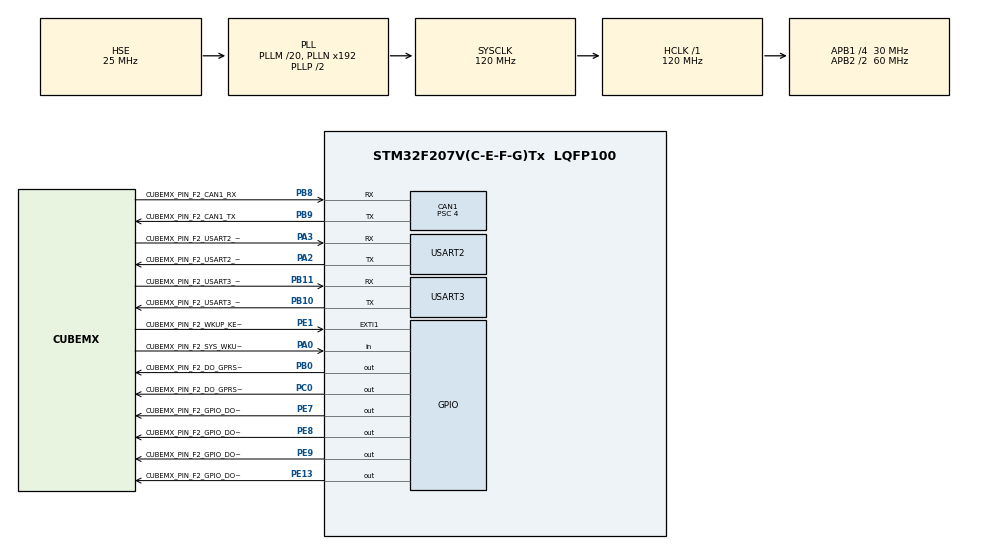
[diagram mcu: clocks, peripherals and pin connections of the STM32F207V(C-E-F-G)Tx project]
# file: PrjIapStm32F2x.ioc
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CAN1.ABOM=ENABLE
CAN1.BS1=CAN_BS1_12TQ
CAN1.BS2=CAN_BS2_2TQ
CAN1.CalculateTimeBit=2000
CAN1.CalculateTimeQuantum=133.33333333333334
CAN1.Prescaler=4
FREERTOS.INCLUDE_eTaskGetState=1
FREERTOS.INCLUDE_pcTaskGetTaskName=1
FREERTOS.INCLUDE_vTaskCleanUpResources=1
FREERTOS.Queues01=myQueue01,16,uint16_t,NULL
FREERTOS.Tasks01=defaultTask,0,512,StartDefaultTask,Default;myTask02,0,512,StartTask02,Default
FREERTOS.Timers01=myTimer01,Callback01,osTimerPeriodic,Default
FREERTOS.configCHECK_FOR_STACK_OVERFLOW=2
FREERTOS.configGENERATE_RUN_TIME_STATS=1
FREERTOS.configMAX_PRIORITIES=31
FREERTOS.configMAX_TASK_NAME_LEN=24
FREERTOS.configMINIMAL_STACK_SIZE=256
FREERTOS.configQUEUE_REGISTRY_SIZE=4
FREERTOS.configTOTAL_HEAP_SIZE=0xCC00
FREERTOS.configUSE_COUNTING_SEMAPHORES=1
FREERTOS.configUSE_IDLE_HOOK=1
FREERTOS.configUSE_MALLOC_FAILED_HOOK=1
FREERTOS.configUSE_PORT_OPTIMISED_TASK_SELECTION=1
FREERTOS.configUSE_RECURSIVE_MUTEXES=1
FREERTOS.configUSE_TICKLESS_IDLE=1
FREERTOS.configUSE_TICK_HOOK=1
FREERTOS.configUSE_TIMERS=1
Mcu.Family=STM32F2
Mcu.Name=STM32F207V(C-E-F-G)Tx
Mcu.Package=LQFP100
NVIC.CAN1_RX0_IRQn=true\:0\:0\:false\:false\:true\:false
NVIC.CAN1_RX1_IRQn=true\:0\:0\:false\:false\:true\:false
NVIC.PriorityGroup=NVIC_PRIORITYGROUP_4
NVIC.TIM1_UP_TIM10_IRQn=true\:0\:0\:false\:false\:true\:false
NVIC.TimeBase=TIM1_UP_TIM10_IRQn
NVIC.TimeBaseIP=TIM1
NVIC.USART2_IRQn=true\:5\:0\:false\:true\:true\:1\:true
NVIC.USART3_IRQn=true\:5\:0\:false\:true\:true\:2\:true
PA0-WKUP.GPIO_Label=CUBEMX_PIN_F2_SYS_WKUP_KEY1
PA0-WKUP.GPIO_PuPd=GPIO_PULLDOWN
PA0-WKUP.Signal=GPIO_Input
PA13.GPIO_Label=CUBEMX_PIN_F2_SYS_JTMS_SWIDO
PA13.Mode=JTAG_5_pins
PA13.Signal=SYS_JTMS-SWDIO
PA14.GPIO_Label=CUBEMX_PIN_F2_SYS_JTCK_SWCLK
PA14.Mode=JTAG_5_pins
PA14.Signal=SYS_JTCK-SWCLK
PA15.GPIO_Label=CUBEMX_PIN_F2_SYS_JDTI
PA15.Mode=JTAG_5_pins
PA15.Signal=SYS_JTDI
PA2.GPIO_Label=CUBEMX_PIN_F2_USART2_TX_GPRS
PA2.Mode=Asynchronous
PA2.Signal=USART2_TX
PA3.GPIO_Label=CUBEMX_PIN_F2_USART2_RX_GPRS
PA3.Mode=Asynchronous
PA3.Signal=USART2_RX
PB0.GPIO_Label=CUBEMX_PIN_F2_DO_GPRSMOD_PWR_SUPPLY
PB0.GPIO_ModeDefaultOutputPP=GPIO_MODE_OUTPUT_PP
PB0.GPIO_PuPd=GPIO_NOPULL
PB0.GPIO_Speed=GPIO_SPEED_FREQ_MEDIUM
PB0.PinState=GPIO_PIN_RESET
PB0.Signal=GPIO_Output
PB10.GPIO_Label=CUBEMX_PIN_F2_USART3_TX_PRINT
PB10.Mode=Asynchronous
PB10.Signal=USART3_TX
PB11.GPIO_Label=CUBEMX_PIN_F2_USART3_RX_PRINT
PB11.Mode=Asynchronous
PB11.Signal=USART3_RX
PB3.GPIO_Label=CUBEMX_PIN_F2_SYS_JTDO_SWO
PB3.Mode=JTAG_5_pins
PB3.Signal=SYS_JTDO-SWO
PB4.GPIO_Label=CUBEMX_PIN_F2_SYS_JTRST
PB4.Mode=JTAG_5_pins
PB4.Signal=SYS_JTRST
PB8.GPIO_Label=CUBEMX_PIN_F2_CAN1_RX
PB8.Mode=Master
PB8.Signal=CAN1_RX
PB9.GPIO_Label=CUBEMX_PIN_F2_CAN1_TX
PB9.Mode=Master
PB9.Signal=CAN1_TX
PC0.GPIO_Label=CUBEMX_PIN_F2_DO_GPRSMOD_PWR_KEY
PC0.GPIO_ModeDefaultOutputPP=GPIO_MODE_OUTPUT_OD
PC0.PinState=GPIO_PIN_SET
PC0.Signal=GPIO_Output
PC14-OSC32_IN.GPIO_Label=CUBEMX_PIN_F2_RCC_OS32_IN
PC14-OSC32_IN.Mode=LSE-External-Oscillator
PC14-OSC32_IN.Signal=RCC_OSC32_IN
PC15-OSC32_OUT.GPIO_Label=CUBEMX_PIN_F2_RCC_OSC32_OUT
PC15-OSC32_OUT.Mode=LSE-External-Oscillator
PC15-OSC32_OUT.Signal=RCC_OSC32_OUT
PE1.GPIO_Label=CUBEMX_PIN_F2_WKUP_KEY2
PE1.Signal=GPXTI1
PE13.GPIO_Label=CUBEMX_PIN_F2_GPIO_DO_BEEP
PE13.Signal=GPIO_Output
PE7.GPIO_Label=CUBEMX_PIN_F2_GPIO_DO_LED_POWER
PE7.Signal=GPIO_Output
PE8.GPIO_Label=CUBEMX_PIN_F2_GPIO_DO_LED_COMMU
PE8.Signal=GPIO_Output
PE9.GPIO_Label=CUBEMX_PIN_F2_GPIO_DO_LED_WORK_STATE
PE9.Signal=GPIO_Output
PH0-OSC_IN.GPIO_Label=CUBEMX_PIN_F2_RCC_OSC_IN
PH0-OSC_IN.Mode=HSE-External-Oscillator
PH0-OSC_IN.Signal=RCC_OSC_IN
PH1-OSC_OUT.GPIO_Label=CUBEMX_PIN_F2_RCC_OSC_OUT
PH1-OSC_OUT.Mode=HSE-External-Oscillator
PH1-OSC_OUT.Signal=RCC_OSC_OUT
ProjectManager.HeapSize=0x200
ProjectManager.StackSize=0x400
ProjectManager.TargetToolchain=MDK-ARM V5
RCC.48MHZClocksFreq_Value=48000000
RCC.AHBFreq_Value=120000000
RCC.APB1CLKDivider=RCC_HCLK_DIV4
RCC.APB1Freq_Value=30000000
RCC.APB1TimFreq_Value=60000000
RCC.APB2CLKDivider=RCC_HCLK_DIV2
RCC.APB2Freq_Value=60000000
RCC.APB2TimFreq_Value=120000000
RCC.CortexFreq_Value=120000000
RCC.FLatency=FLASH_LATENCY_3
RCC.HCLKFreq_Value=120000000
RCC.HSE_VALUE=25000000
RCC.HSI_VALUE=16000000
RCC.PLLM=20
RCC.PLLQ=5
RCC.PLLSourceVirtual=RCC_PLLSOURCE_HSE
RCC.SYSCLKFreq_VALUE=120000000
RCC.SYSCLKSource=RCC_SYSCLKSOURCE_PLLCLK
RCC.VCOOutputFreq_Value=240000000
RTC.Date=2
RTC.Hours=21
RTC.Minutes=20
RTC.Seconds=40
RTC.Year=17
VP_FREERTOS_VS_ENABLE.Mode=Enabled
VP_RTC_VS_RTC_Activate.Mode=RTC_Enabled
VP_RTC_VS_RTC_Calendar.Mode=RTC_Calendar
VP_SYS_VS_tim1.Mode=TIM1
board=PrjIapStm32F2x

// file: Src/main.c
/**
  ******************************************************************************
  * File Name          : main.c
  * Description        : Main program body
  ******************************************************************************
  *
  * Copyright (c) 2017 STMicroelectronics International N.V.
  * All rights reserved.
  *
  * Redistribution and use in source and binary forms, with or without
  * modification, are permitted, provided that the following conditions are met:
  *
  * 1. Redistribution of source code must retain the above copyright notice,
  *    this list of conditions and the following disclaimer.
  * 2. Redistributions in binary form must reproduce the above copyright notice,
  *    this list of conditions and the following disclaimer in the documentation
  *    and/or other materials provided with the distribution.
  * 3. Neither the name of STMicroelectronics nor the names of other
  *    contributors to this software may be used to endorse or promote products
  *    derived from this software without specific written permission.
  * 4. This software, including modifications and/or derivative works of this
  *    software, must execute solely and exclusively on microcontroller or
  *    microprocessor devices manufactured by or for STMicroelectronics.
  * 5. Redistribution and use of this software other than as permitted under
  *    this license is void and will automatically terminate your rights under
  *    this license.
  *
  * THIS SOFTWARE IS PROVIDED BY STMICROELECTRONICS AND CONTRIBUTORS "AS IS"
  * AND ANY EXPRESS, IMPLIED OR STATUTORY WARRANTIES, INCLUDING, BUT NOT
  * LIMITED TO, THE IMPLIED WARRANTIES OF MERCHANTABILITY, FITNESS FOR A
  * PARTICULAR PURPOSE AND NON-INFRINGEMENT OF THIRD PARTY INTELLECTUAL PROPERTY
  * RIGHTS ARE DISCLAIMED TO THE FULLEST EXTENT PERMITTED BY LAW. IN NO EVENT
  * SHALL STMICROELECTRONICS OR CONTRIBUTORS BE LIABLE FOR ANY DIRECT, INDIRECT,
  * INCIDENTAL, SPECIAL, EXEMPLARY, OR CONSEQUENTIAL DAMAGES (INCLUDING, BUT NOT
  * LIMITED TO, PROCUREMENT OF SUBSTITUTE GOODS OR SERVICES; LOSS OF USE, DATA,
  * OR PROFITS; OR BUSINESS INTERRUPTION) HOWEVER CAUSED AND ON ANY THEORY OF
  * LIABILITY, WHETHER IN CONTRACT, STRICT LIABILITY, OR TORT (INCLUDING
  * NEGLIGENCE OR OTHERWISE) ARISING IN ANY WAY OUT OF THE USE OF THIS SOFTWARE,
  * EVEN IF ADVISED OF THE POSSIBILITY OF SUCH DAMAGE.
  *
  ******************************************************************************
  */
#include "main.h"
#include "stm32f2xx_hal.h"
#include "cmsis_os.h"
#include "can.h"
#include "rtc.h"
#include "usart.h"
#include "gpio.h"

/* USER CODE BEGIN Includes */
#include "l3iap.h"

/* USER CODE END Includes */

/* USER CODE BEGIN PV */
/* Private variables ---------------------------------------------------------*/
uint8_t zIhuUartRxBuffer[6];
uint8_t zIhuSpiRxBuffer[2];
uint8_t zIhuI2cRxBuffer[2];

/* USER CODE END PV */

void SystemClock_Config(void);
void Error_Handler(void);
void MX_FREERTOS_Init(void);
static void MX_NVIC_Init(void);

/* USER CODE BEGIN PFP */
/* Private function prototypes -----------------------------------------------*/

/* USER CODE END PFP */

int main(void)
{

  /* MCU Configuration----------------------------------------------------------*/

  /* Reset of all peripherals, Initializes the Flash interface and the Systick. */
  HAL_Init();

  /* Configure the system clock */
  SystemClock_Config();

  /* Initialize all configured peripherals */
  MX_GPIO_Init();
  MX_RTC_Init();
  MX_USART2_UART_Init();
  MX_USART3_UART_Init();
  MX_CAN1_Init();

  /* Initialize interrupts */
  MX_NVIC_Init();

  /* USER CODE BEGIN 2 */
  HAL_UART_Receive_IT(&huart2,&zIhuUartRxBuffer[1],1);
  HAL_UART_Receive_IT(&huart3,&zIhuUartRxBuffer[2],1);

	/*
	** THIS IS USED TO INIT CAN INTERFACE:
	** MAKE SURE bsp_can_config_filter() called after bsp_can_init() & func_bfsc_hw_init();
	*/
	//bsp_can_init(&hcan1, 0x10);
	HAL_CAN_Receive_IT(&hcan1, 0);

	ihu_bsp_stm32_led_commu_f2board_on();
	//ihu_bsp_stm32_led_serv1_f2board_on();
	ihu_bsp_stm32_led_work_state_f2board_on();

	/* CREATE IHU VM */
	ihu_vm_main();
	printf("ihu_vm_main() launched...\r\n");

  /* USER CODE END 2 */

  /* Call init function for freertos objects (in freertos.c) */
  MX_FREERTOS_Init();

  /* Start scheduler */
  osKernelStart();

  /* We should never get here as control is now taken by the scheduler */

  /* Infinite loop */
  while (1)
  {

  }

}

/** System Clock Configuration
*/
void SystemClock_Config(void)
{

  RCC_OscInitTypeDef RCC_OscInitStruct;
  RCC_ClkInitTypeDef RCC_ClkInitStruct;
  RCC_PeriphCLKInitTypeDef PeriphClkInitStruct;

    /**Initializes the CPU, AHB and APB busses clocks
    */
  RCC_OscInitStruct.OscillatorType = RCC_OSCILLATORTYPE_LSI|RCC_OSCILLATORTYPE_HSE;
  RCC_OscInitStruct.HSEState = RCC_HSE_ON;
  RCC_OscInitStruct.LSIState = RCC_LSI_ON;
  RCC_OscInitStruct.PLL.PLLState = RCC_PLL_ON;
  RCC_OscInitStruct.PLL.PLLSource = RCC_PLLSOURCE_HSE;
  RCC_OscInitStruct.PLL.PLLM = 20;
  RCC_OscInitStruct.PLL.PLLN = 192;
  RCC_OscInitStruct.PLL.PLLP = RCC_PLLP_DIV2;
  RCC_OscInitStruct.PLL.PLLQ = 5;
  if (HAL_RCC_OscConfig(&RCC_OscInitStruct) != HAL_OK)
  {
    Error_Handler();
  }

    /**Initializes the CPU, AHB and APB busses clocks
    */
  RCC_ClkInitStruct.ClockType = RCC_CLOCKTYPE_HCLK|RCC_CLOCKTYPE_SYSCLK
                              |RCC_CLOCKTYPE_PCLK1|RCC_CLOCKTYPE_PCLK2;
  RCC_ClkInitStruct.SYSCLKSource = RCC_SYSCLKSOURCE_PLLCLK;
  RCC_ClkInitStruct.AHBCLKDivider = RCC_SYSCLK_DIV1;
  RCC_ClkInitStruct.APB1CLKDivider = RCC_HCLK_DIV4;
  RCC_ClkInitStruct.APB2CLKDivider = RCC_HCLK_DIV2;

  if (HAL_RCC_ClockConfig(&RCC_ClkInitStruct, FLASH_LATENCY_3) != HAL_OK)
  {
    Error_Handler();
  }

  PeriphClkInitStruct.PeriphClockSelection = RCC_PERIPHCLK_RTC;
  PeriphClkInitStruct.RTCClockSelection = RCC_RTCCLKSOURCE_LSI;
  if (HAL_RCCEx_PeriphCLKConfig(&PeriphClkInitStruct) != HAL_OK)
  {
    Error_Handler();
  }

    /**Configure the Systick interrupt time
    */
  HAL_SYSTICK_Config(HAL_RCC_GetHCLKFreq()/1000);

    /**Configure the Systick
    */
  HAL_SYSTICK_CLKSourceConfig(SYSTICK_CLKSOURCE_HCLK);

  /* SysTick_IRQn interrupt configuration */
  HAL_NVIC_SetPriority(SysTick_IRQn, 15, 0);
}

/** NVIC Configuration
*/
static void MX_NVIC_Init(void)
{
  /* USART2_IRQn interrupt configuration */
  HAL_NVIC_SetPriority(USART2_IRQn, 5, 0);
  HAL_NVIC_EnableIRQ(USART2_IRQn);
  /* USART3_IRQn interrupt configuration */
  HAL_NVIC_SetPriority(USART3_IRQn, 5, 0);
  HAL_NVIC_EnableIRQ(USART3_IRQn);
}

void HAL_TIM_PeriodElapsedCallback(TIM_HandleTypeDef *htim)
{
  if (htim->Instance == TIM1) {
    HAL_IncTick();
  }
}

void Error_Handler(void)
{
  while(1)
  {
  }
}

/************************ (C) COPYRIGHT STMicroelectronics *****END OF FILE****/

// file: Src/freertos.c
/**
  ******************************************************************************
  * File Name          : freertos.c
  * Description        : Code for freertos applications
  ******************************************************************************
  *
  * Copyright (c) 2017 STMicroelectronics International N.V.
  * All rights reserved.
  *
  * Redistribution and use in source and binary forms, with or without
  * modification, are permitted, provided that the following conditions are met:
  *
  * 1. Redistribution of source code must retain the above copyright notice,
  *    this list of conditions and the following disclaimer.
  * 2. Redistributions in binary form must reproduce the above copyright notice,
  *    this list of conditions and the following disclaimer in the documentation
  *    and/or other materials provided with the distribution.
  * 3. Neither the name of STMicroelectronics nor the names of other
  *    contributors to this software may be used to endorse or promote products
  *    derived from this software without specific written permission.
  * 4. This software, including modifications and/or derivative works of this
  *    software, must execute solely and exclusively on microcontroller or
  *    microprocessor devices manufactured by or for STMicroelectronics.
  * 5. Redistribution and use of this software other than as permitted under
  *    this license is void and will automatically terminate your rights under
  *    this license.
  *
  * THIS SOFTWARE IS PROVIDED BY STMICROELECTRONICS AND CONTRIBUTORS "AS IS"
  * AND ANY EXPRESS, IMPLIED OR STATUTORY WARRANTIES, INCLUDING, BUT NOT
  * LIMITED TO, THE IMPLIED WARRANTIES OF MERCHANTABILITY, FITNESS FOR A
  * PARTICULAR PURPOSE AND NON-INFRINGEMENT OF THIRD PARTY INTELLECTUAL PROPERTY
  * RIGHTS ARE DISCLAIMED TO THE FULLEST EXTENT PERMITTED BY LAW. IN NO EVENT
  * SHALL STMICROELECTRONICS OR CONTRIBUTORS BE LIABLE FOR ANY DIRECT, INDIRECT,
  * INCIDENTAL, SPECIAL, EXEMPLARY, OR CONSEQUENTIAL DAMAGES (INCLUDING, BUT NOT
  * LIMITED TO, PROCUREMENT OF SUBSTITUTE GOODS OR SERVICES; LOSS OF USE, DATA,
  * OR PROFITS; OR BUSINESS INTERRUPTION) HOWEVER CAUSED AND ON ANY THEORY OF
  * LIABILITY, WHETHER IN CONTRACT, STRICT LIABILITY, OR TORT (INCLUDING
  * NEGLIGENCE OR OTHERWISE) ARISING IN ANY WAY OUT OF THE USE OF THIS SOFTWARE,
  * EVEN IF ADVISED OF THE POSSIBILITY OF SUCH DAMAGE.
  *
  ******************************************************************************
  */

#include "FreeRTOS.h"
#include "task.h"
#include "cmsis_os.h"

osThreadId defaultTaskHandle;
osThreadId myTask02Handle;
osMessageQId myQueue01Handle;
osTimerId myTimer01Handle;

void StartDefaultTask(void const * argument);
void StartTask02(void const * argument);
void Callback01(void const * argument);

void MX_FREERTOS_Init(void); /* (MISRA C 2004 rule 8.1) */

/* Pre/Post sleep processing prototypes */
void PreSleepProcessing(uint32_t *ulExpectedIdleTime);
void PostSleepProcessing(uint32_t *ulExpectedIdleTime);

/* Hook prototypes */
void configureTimerForRunTimeStats(void);
unsigned long getRunTimeCounterValue(void);
void vApplicationIdleHook(void);
void vApplicationTickHook(void);
void vApplicationStackOverflowHook(xTaskHandle xTask, signed char *pcTaskName);
void vApplicationMallocFailedHook(void);

/* USER CODE BEGIN 1 */
/* Functions needed when configGENERATE_RUN_TIME_STATS is on */
void configureTimerForRunTimeStats(void)
{

}

unsigned long getRunTimeCounterValue(void)
{
return 0;
}
/* USER CODE END 1 */

/* USER CODE BEGIN 2 */
void vApplicationIdleHook( void )
{
   /* vApplicationIdleHook() will only be called if configUSE_IDLE_HOOK is set
   to 1 in FreeRTOSConfig.h. It will be called on each iteration of the idle
   task. It is essential that code added to this hook function never attempts
   to block in any way (for example, call xQueueReceive() with a block time
   specified, or call vTaskDelay()). If the application makes use of the
   vTaskDelete() API function (as this demo application does) then it is also
   important that vApplicationIdleHook() is permitted to return to its calling
   function, because it is the responsibility of the idle task to clean up
   memory allocated by the kernel to any task that has since been deleted. */
}
/* USER CODE END 2 */

/* USER CODE BEGIN 3 */
void vApplicationTickHook( void )
{
   /* This function will be called by each tick interrupt if
   configUSE_TICK_HOOK is set to 1 in FreeRTOSConfig.h. User code can be
   added here, but the tick hook is called from an interrupt context, so
   code must not attempt to block, and only the interrupt safe FreeRTOS API
   functions can be used (those that end in FromISR()). */
}
/* USER CODE END 3 */

/* USER CODE BEGIN 4 */
void vApplicationStackOverflowHook(xTaskHandle xTask, signed char *pcTaskName)
{
   /* Run time stack overflow checking is performed if
   configCHECK_FOR_STACK_OVERFLOW is defined to 1 or 2. This hook function is
   called if a stack overflow is detected. */
}
/* USER CODE END 4 */

/* USER CODE BEGIN 5 */
void vApplicationMallocFailedHook(void)
{
   /* vApplicationMallocFailedHook() will only be called if
   configUSE_MALLOC_FAILED_HOOK is set to 1 in FreeRTOSConfig.h. It is a hook
   function that will get called if a call to pvPortMalloc() fails.
   pvPortMalloc() is called internally by the kernel whenever a task, queue,
   timer or semaphore is created. It is also called by various parts of the
   demo application. If heap_1.c or heap_2.c are used, then the size of the
   heap available to pvPortMalloc() is defined by configTOTAL_HEAP_SIZE in
   FreeRTOSConfig.h, and the xPortGetFreeHeapSize() API function can be used
   to query the size of free heap space that remains (although it does not
   provide information on how the remaining heap might be fragmented). */
}
/* USER CODE END 5 */

/* USER CODE BEGIN PREPOSTSLEEP */
void PreSleepProcessing(uint32_t *ulExpectedIdleTime)
{
/* place for user code */
}

void PostSleepProcessing(uint32_t *ulExpectedIdleTime)
{
/* place for user code */
}
/* USER CODE END PREPOSTSLEEP */

/* Init FreeRTOS */

void MX_FREERTOS_Init(void) {

  /* Create the timer(s) */
  /* definition and creation of myTimer01 */
  osTimerDef(myTimer01, Callback01);
  myTimer01Handle = osTimerCreate(osTimer(myTimer01), osTimerPeriodic, NULL);

  /* Create the thread(s) */
  /* definition and creation of defaultTask */
  osThreadDef(defaultTask, StartDefaultTask, osPriorityNormal, 0, 512);
  defaultTaskHandle = osThreadCreate(osThread(defaultTask), NULL);

  /* definition and creation of myTask02 */
  osThreadDef(myTask02, StartTask02, osPriorityNormal, 0, 512);
  myTask02Handle = osThreadCreate(osThread(myTask02), NULL);

  /* Create the queue(s) */
  /* definition and creation of myQueue01 */
  osMessageQDef(myQueue01, 16, uint16_t);
  myQueue01Handle = osMessageCreate(osMessageQ(myQueue01), NULL);

}

/* StartDefaultTask function */
void StartDefaultTask(void const * argument)
{

  for(;;)
  {
    osDelay(1);
  }
}

/* StartTask02 function */
void StartTask02(void const * argument)
{
  for(;;)
  {
    osDelay(1);
  }
}

/* Callback01 function */
void Callback01(void const * argument)
{
}

/************************ (C) COPYRIGHT STMicroelectronics *****END OF FILE****/
